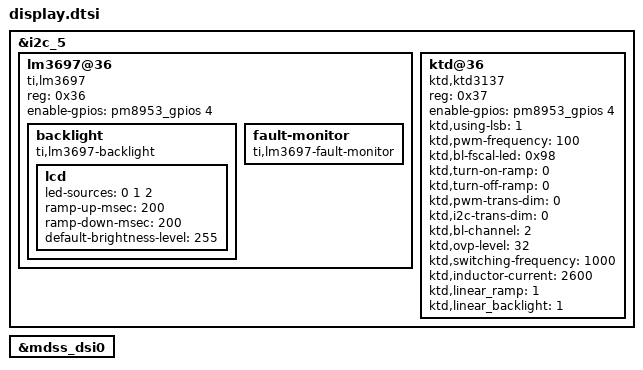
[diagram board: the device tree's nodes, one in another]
/* From stock sdm439-mtp.dtsi */
&i2c_5 {
	lm3697@36 {
		compatible = "ti,lm3697";
		reg = <0x36>;

		enable-gpios = <&pm8953_gpios 4 0>;

		backlight {
			compatible = "ti,lm3697-backlight";

			lcd {
				led-sources = <0 1 2>;
				ramp-up-msec = <200>;
				ramp-down-msec = <200>;
				/*pwm-period = <0>;*/
				default-brightness-level = <255>;
			};
		};

		fault-monitor {
			compatible = "ti,lm3697-fault-monitor";
		};
	};

	ktd@36 {
		compatible = "ktd,ktd3137";
		reg = <0x37>;
		enable-gpios = <&pm8953_gpios 4 0>;
		/*ktd,pwm-mode; */
		ktd,using-lsb = <1>;
		ktd,pwm-frequency = <100>;
		ktd,bl-fscal-led = <0x98>;/*default 20.2mA*/
		ktd,turn-on-ramp = <0>;
		ktd,turn-off-ramp = <0>;
		ktd,pwm-trans-dim = <0>;
		ktd,i2c-trans-dim = <0>;
		ktd,bl-channel = <2>;
		ktd,ovp-level = <32>; /*default 32v*/
		ktd,switching-frequency = <1000>; /*default 1000kHz*/
		ktd,inductor-current = <2600>; //default 2600mA
		ktd,linear_ramp = <1>; /*default is exponential*/
		ktd,linear_backlight = <1>; /*default is exponential*/
	};
};

&mdss_dsi0 {
	/delete-property/ qcom,platform-bklight-en-gpio;
};
